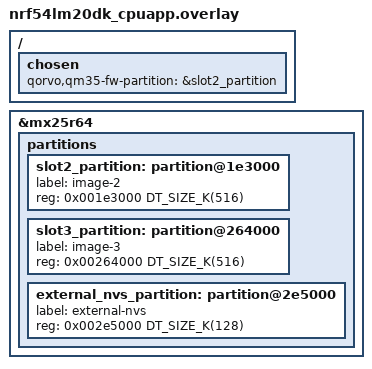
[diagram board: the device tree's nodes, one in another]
/*
 * Copyright (c) 2026 Nordic Semiconductor ASA
 *
 * SPDX-License-Identifier: LicenseRef-Nordic-5-Clause
 */

/delete-node/ &external_nvs_partition;

/ {
	chosen {
		qorvo,qm35-fw-partition = &slot2_partition;
	};
};

&mx25r64 {
	status = "okay";

	partitions {
		slot2_partition: partition@1e3000 {
			label = "image-2";
			reg = <0x001e3000 DT_SIZE_K(516)>;
		};

		slot3_partition: partition@264000 {
			label = "image-3";
			reg = <0x00264000 DT_SIZE_K(516)>;
		};

		external_nvs_partition: partition@2e5000 {
			label = "external-nvs";
			reg = <0x002e5000 DT_SIZE_K(128)>;
		};
	};
};
